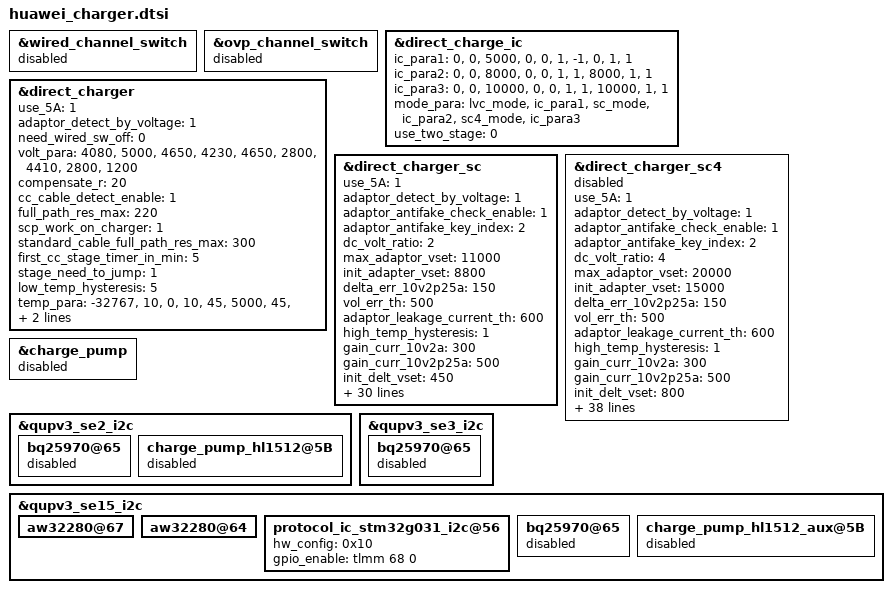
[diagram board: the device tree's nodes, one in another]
&wired_channel_switch {
	status = "disabled";
};

&ovp_channel_switch {
	status = "disabled";
};

&direct_charge_ic {
	/* The IC_PARA table is used to find the relationship between chip and path */
	/* the chip's current passing capacity */
	/* and the sampling points of battery voltage and current */
	/* ic_index  path_index  max_ibat  ibat_sample_point  vbat_sample_point */
	ic_para1 =
		"0", "0", "5000", "0", "0",
		"1", "-1", "0", "1", "1";
	ic_para2 =
		"0", "0", "8000", "0", "0",
		"1", "1", "8000", "1", "1";
	ic_para3 =
		"0", "0", "10000", "0", "0",
		"1", "1", "10000", "1", "1";
	mode_para =
		"lvc_mode", "ic_para1",
		"sc_mode", "ic_para2",
		"sc4_mode", "ic_para3";
	use_two_stage = <0>;
	status = "ok";
};

&direct_charger {
	use_5A = <1>;
	adaptor_detect_by_voltage = <1>;
	need_wired_sw_off = <0>;
	volt_para =
		"4080", "5000", "4650",
		"4230", "4650", "2800",
		"4410", "2800", "1200";
	compensate_r = <20>;
	cc_cable_detect_enable = <1>;
	full_path_res_max = <220>;
	scp_work_on_charger = <1>;
	standard_cable_full_path_res_max = <300>;
	first_cc_stage_timer_in_min = <5>;
	stage_need_to_jump = "1";
	low_temp_hysteresis = <5>;
	temp_para =
		"-32767", "10", "0",
		"10", "45", "5000",
		"45", "32767", "0";
	rt_test_para =
		"1000", "105"; /* rt_curr_th rt_test_time */
	status = "ok";

};

&direct_charger_sc {
	use_5A = <1>;
	adaptor_detect_by_voltage = <1>;
	adaptor_antifake_check_enable = <1>;
	adaptor_antifake_key_index = <2>;
	dc_volt_ratio = <2>;
	max_adaptor_vset = <11000>;
	init_adapter_vset = <8800>;
	delta_err_10v2p25a = <150>;
	vol_err_th = <500>;
	adaptor_leakage_current_th = <600>;
	high_temp_hysteresis = <1>;
	gain_curr_10v2a = <300>;
	gain_curr_10v2p25a = <500>;
	init_delt_vset = <450>;
	vstep = <20>;
	max_dc_bat_vol = <4380>;
	max_current_for_none_standard_cable = <6000>;
	volt_para =
		"4150", "8000", "6000",
		"4250", "6000", "4000",
		"4300", "4000", "2900",
		"4400", "2900", "1000";
	volt_para1 =
		"4250", "12000", "8000",
		"4300", "8000", "6000",
		"4380", "6000", "4800",
		"4430", "4800", "4000",
		"4400", "4000", "1000";
	bat_para =
		"CAE", "10", "20", "volt_para",
		"CAE", "20", "45", "volt_para1",
		"default", "10", "20", "volt_para",
		"default", "20", "45", "volt_para1";
	vstep_para =
			"2000", "80";
	compensate_r = <0>;
	cc_cable_detect_enable = <1>;
	full_path_res_max = <500>;
	scp_work_on_charger = <1>;
	standard_cable_full_path_res_max = <500>;
	first_cc_stage_timer_in_min = <14>;
	stage_need_to_jump = "-1";
	is_show_ico_first = <1>;
	is_send_cable_type = <0>;
	support_multi_ic = <1>;
	rt_test_para =
		/* first:sc second:mainsc third:auxsc */
		"500", "105",
		"500", "105",
		"500", "105";
	temp_para =
		"-32767", "10", "0",
		"10", "45", "12500",
		"45", "32767", "0";
	resist_para =
		"0", "300", "6000",
		"300", "500", "5000";
	std_resist_para =
		"0", "300", "12500",
		"300", "500", "5000";
	10v2p25a_cur_para =
		"-32767", "5500",  "2000",
		"5500",   "9000",  "2500",
		"9000",   "10000", "2250",
		"10000",  "10500", "2000",
		"10500",  "32767", "1500";
	status = "ok";
};

&direct_charger_sc4 {
	use_5A = <1>;
	adaptor_detect_by_voltage = <1>;
	adaptor_antifake_check_enable = <1>;
	adaptor_antifake_key_index = <2>;
	dc_volt_ratio = <4>;
	max_adaptor_vset = <20000>;
	init_adapter_vset = <15000>;
	delta_err_10v2p25a = <150>;
	vol_err_th = <500>;
	adaptor_leakage_current_th = <600>;
	high_temp_hysteresis = <1>;
	gain_curr_10v2a = <300>;
	gain_curr_10v2p25a = <500>;
	init_delt_vset = <800>;
	vstep = <40>;
	min_dc_bat_vol = <3450>;
	max_dc_bat_vol = <4380>;
	delta_err = <200>;
	ctc_cable_full_path_res_max = <600>;
	max_current_for_none_standard_cable = <20000>;
	volt_para =
		"4100", "20000", "16000",
		"4200", "16000", "12000",
		"4300", "12000", "8000",
		"4400", "8000", "6000",
		"4430", "6000", "4800",
		"4460", "4800", "1600";
	volt_para1 =
		"4100", "20000", "16000",
		"4200", "16000", "12000",
		"4300", "12000", "8000",
		"4400", "8000", "6000",
		"4430", "6000", "4800",
		"4460", "4800", "1600";
	time_para =
		"840", "8000",
		"420", "10000",
		"360", "12000",
		"300", "14000",
		"120", "16000";
	bat_para =
		"CAE", "10", "20", "volt_para",
		"CAE", "20", "45", "volt_para1",
		"default", "10", "20", "volt_para",
		"default", "20", "45", "volt_para1";
	vbat_comp_para =
		"aw32280", "-55", "-55";
	vstep_para =
			"2000", "80";
	compensate_r = <0>;
	cc_cable_detect_enable = <1>;
	full_path_res_max = <500>;
	scp_work_on_charger = <1>;
	standard_cable_full_path_res_max = <500>;
	first_cc_stage_timer_in_min = <14>;
	stage_need_to_jump = "-1";
	is_show_ico_first = <1>;
	is_send_cable_type = <0>;
	support_multi_ic = <1>;
	rt_test_para =
		/* first:sc second:mainsc third:auxsc */
		"500", "105",
		"500", "105",
		"500", "105";
	temp_para =
		"-32767", "10", "0",
		"10", "45", "20000",
		"45", "32767", "0";
	resist_para =
		"0", "300", "20000",
		"300", "500", "20000";
	std_resist_para =
		"0", "300", "20000",
		"300", "500", "20000";
	10v2p25a_cur_para =
		"-32767", "5500",  "2000",
		"5500",   "9000",  "2500",
		"9000",   "10000", "2250",
		"10000",  "10500", "2000",
		"10500",  "32767", "1500";
	status = "disabled";
};

&charge_pump {
	status = "disabled";
};

&qupv3_se2_i2c {
	bq25970@65 {
		status = "disabled";
	};

	charge_pump_hl1512@5B {
		status = "disabled";
	};
};

&qupv3_se3_i2c {
	bq25970@65 {
		status = "disabled";
	};
};

&qupv3_se15_i2c {
	aw32280@67{
		status = "ok";
	};

	aw32280@64{
		status = "ok";
	};

	protocol_ic_stm32g031_i2c@56 {
		hw_config = <0x10>;
		gpio_enable = <&tlmm 68 0>;
		status = "ok";
	};

	bq25970@65 {
		status = "disabled";
	};

	charge_pump_hl1512_aux@5B {
		status = "disabled";
	};
};
